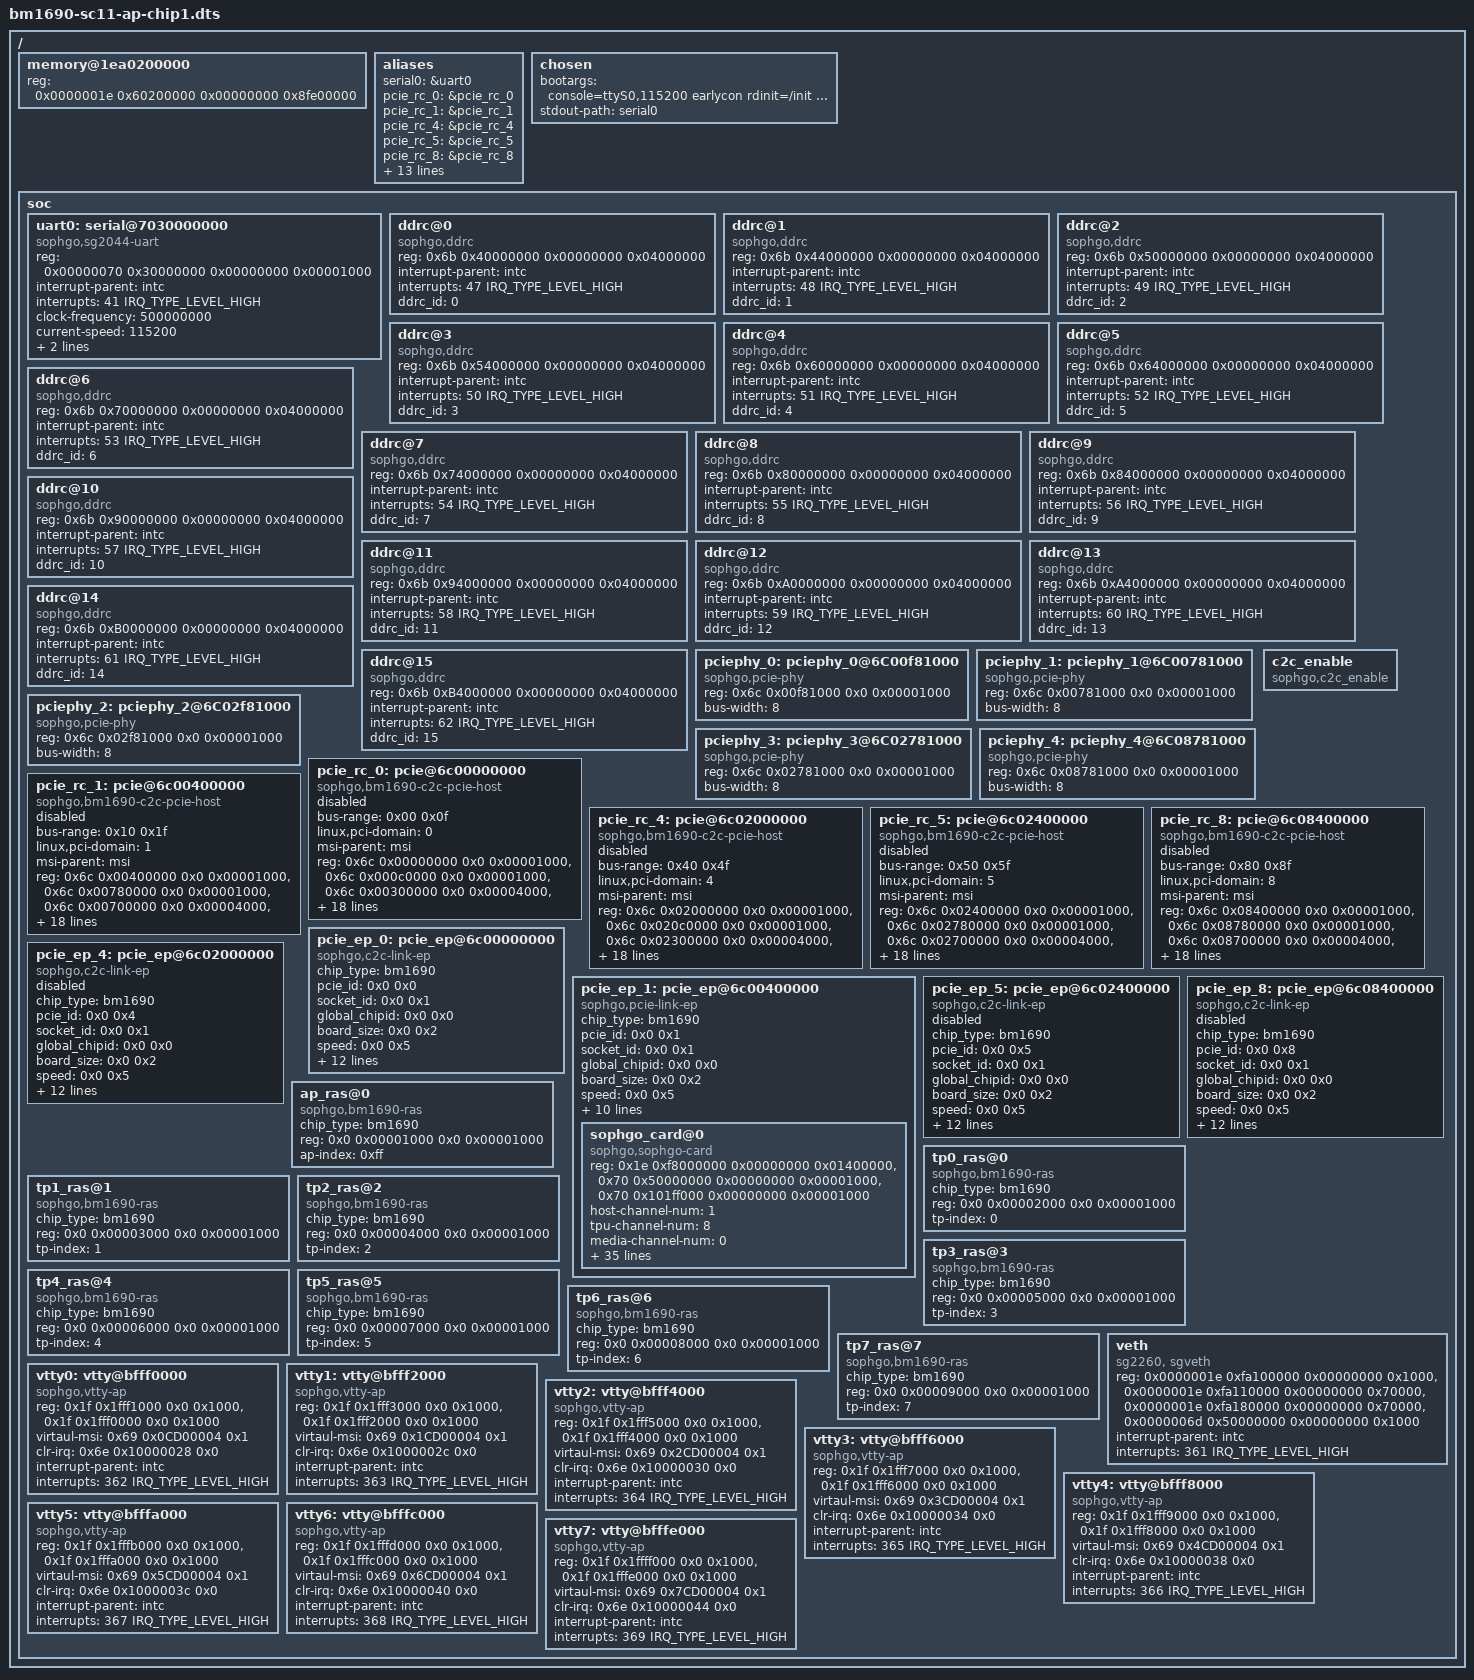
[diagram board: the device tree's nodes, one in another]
// SPDX-License-Identifier: (GPL-2.0 OR MIT)
/*
 * Copyright (C) 2022 Sophgo Technology Inc. All rights reserved.
 */

/dts-v1/;
#include <dt-bindings/interrupt-controller/irq.h>
#include <dt-bindings/reset/sophgo,sg2044-reset.h>
#include <dt-bindings/clock/sophgo,sg2044-clock.h>
#include "bm1690-cpu-ap.dtsi"
#include "bm1690-clock.dtsi"
#include "sg2044-pinctrl.dtsi"
#include "sg2044-peri-sys.dtsi"
#include "bm1690-pcie-msi.dtsi"

/delete-node/ &emmc;

/ {
	/delete-node/ memory@80200000;
	memory@1ea0200000 {
		device_type = "memory";
		reg = <0x0000001e 0x60200000 0x00000000 0x8fe00000>;
	};

	aliases {
		serial0 = &uart0;
		pcie_rc_0 = &pcie_rc_0;
		pcie_rc_1 = &pcie_rc_1;
		pcie_rc_4 = &pcie_rc_4;
		pcie_rc_5 = &pcie_rc_5;
		pcie_rc_8 = &pcie_rc_8;
		pcie_ep_0 = &pcie_ep_0;
		pcie_ep_1 = &pcie_ep_1;
		pcie_ep_4 = &pcie_ep_4;
		pcie_ep_5 = &pcie_ep_5;
		pcie_ep_8 = &pcie_ep_8;
		vtty0 = &vtty0;
		vtty1 = &vtty1;
		vtty2 = &vtty2;
		vtty3 = &vtty3;
		vtty4 = &vtty4;
		vtty5 = &vtty5;
		vtty6 = &vtty6;
		vtty7 = &vtty7;
	};

	chosen {
		bootargs = "console=ttyS0,115200 earlycon rdinit=/init root=/dev/ram0 rw initrd=0x1eab000000,64M maxcpus=4";
		stdout-path = "serial0";
	};

	soc {
		uart0: serial@7030000000 {
			compatible = "sophgo,sg2044-uart", "snps,dw-apb-uart";
			reg = <0x00000070 0x30000000 0x00000000 0x00001000>;
			interrupt-parent = <&intc>;
			interrupts = <41 IRQ_TYPE_LEVEL_HIGH>;
			clock-frequency = <500000000>;
			current-speed = <115200>;
			reg-shift = <2>;
			reg-io-width = <4>;
		};

		ddrc@0 {
			compatible = "sophgo,ddrc";

			reg = <0x6b 0x40000000 0x00000000 0x04000000>;
			interrupt-parent = <&intc>;
			interrupts = <47 IRQ_TYPE_LEVEL_HIGH>;
			// trigger_error_index = <0x0201060c>;
			ddrc_id = <0>;
		};
		ddrc@1 {
			compatible = "sophgo,ddrc";

			reg = <0x6b 0x44000000 0x00000000 0x04000000>;
			interrupt-parent = <&intc>;
			interrupts = <48 IRQ_TYPE_LEVEL_HIGH>;
			// trigger_error_index = <0x0201060c>;
			ddrc_id = <1>;
		};
		ddrc@2 {
			compatible = "sophgo,ddrc";

			reg = <0x6b 0x50000000 0x00000000 0x04000000>;
			interrupt-parent = <&intc>;
			interrupts = <49 IRQ_TYPE_LEVEL_HIGH>;
			// trigger_error_index = <0x0201060c>;
			ddrc_id = <2>;
		};
		ddrc@3 {
			compatible = "sophgo,ddrc";

			reg = <0x6b 0x54000000 0x00000000 0x04000000>;
			interrupt-parent = <&intc>;
			interrupts = <50 IRQ_TYPE_LEVEL_HIGH>;
			// trigger_error_index = <0x0201060c>;
			ddrc_id = <3>;
		};
		ddrc@4 {
			compatible = "sophgo,ddrc";

			reg = <0x6b 0x60000000 0x00000000 0x04000000>;
			interrupt-parent = <&intc>;
			interrupts = <51 IRQ_TYPE_LEVEL_HIGH>;
			// trigger_error_index = <0x0201060c>;
			ddrc_id = <4>;
		};
		ddrc@5 {
			compatible = "sophgo,ddrc";

			reg = <0x6b 0x64000000 0x00000000 0x04000000>;
			interrupt-parent = <&intc>;
			interrupts = <52 IRQ_TYPE_LEVEL_HIGH>;
			// trigger_error_index = <0x0201060c>;
			ddrc_id = <5>;
		};
		ddrc@6 {
			compatible = "sophgo,ddrc";

			reg = <0x6b 0x70000000 0x00000000 0x04000000>;
			interrupt-parent = <&intc>;
			interrupts = <53 IRQ_TYPE_LEVEL_HIGH>;
			// trigger_error_index = <0x0201060c>;
			ddrc_id = <6>;
		};
		ddrc@7 {
			compatible = "sophgo,ddrc";

			reg = <0x6b 0x74000000 0x00000000 0x04000000>;
			interrupt-parent = <&intc>;
			interrupts = <54 IRQ_TYPE_LEVEL_HIGH>;
			// trigger_error_index = <0x0201060c>;
			ddrc_id = <7>;
		};
		ddrc@8 {
			compatible = "sophgo,ddrc";

			reg = <0x6b 0x80000000 0x00000000 0x04000000>;
			interrupt-parent = <&intc>;
			interrupts = <55 IRQ_TYPE_LEVEL_HIGH>;
			// trigger_error_index = <0x0201060c>;
			ddrc_id = <8>;
		};
		ddrc@9 {
			compatible = "sophgo,ddrc";

			reg = <0x6b 0x84000000 0x00000000 0x04000000>;
			interrupt-parent = <&intc>;
			interrupts = <56 IRQ_TYPE_LEVEL_HIGH>;
			// trigger_error_index = <0x0201060c>;
			ddrc_id = <9>;
		};
		ddrc@10 {
			compatible = "sophgo,ddrc";

			reg = <0x6b 0x90000000 0x00000000 0x04000000>;
			interrupt-parent = <&intc>;
			interrupts = <57 IRQ_TYPE_LEVEL_HIGH>;
			// trigger_error_index = <0x0201060c>;
			ddrc_id = <10>;
		};
		ddrc@11 {
			compatible = "sophgo,ddrc";

			reg = <0x6b 0x94000000 0x00000000 0x04000000>;
			interrupt-parent = <&intc>;
			interrupts = <58 IRQ_TYPE_LEVEL_HIGH>;
			// trigger_error_index = <0x0201060c>;
			ddrc_id = <11>;
		};
		ddrc@12 {
			compatible = "sophgo,ddrc";

			reg = <0x6b 0xA0000000 0x00000000 0x04000000>;
			interrupt-parent = <&intc>;
			interrupts = <59 IRQ_TYPE_LEVEL_HIGH>;
			// trigger_error_index = <0x0201060c>;
			ddrc_id = <12>;
		};
		ddrc@13 {
			compatible = "sophgo,ddrc";

			reg = <0x6b 0xA4000000 0x00000000 0x04000000>;
			interrupt-parent = <&intc>;
			interrupts = <60 IRQ_TYPE_LEVEL_HIGH>;
			// trigger_error_index = <0x0201060c>;
			ddrc_id = <13>;
		};
		ddrc@14 {
			compatible = "sophgo,ddrc";

			reg = <0x6b 0xB0000000 0x00000000 0x04000000>;
			interrupt-parent = <&intc>;
			interrupts = <61 IRQ_TYPE_LEVEL_HIGH>;
			// trigger_error_index = <0x0201060c>;
			ddrc_id = <14>;
		};
		ddrc@15 {
			compatible = "sophgo,ddrc";

			reg = <0x6b 0xB4000000 0x00000000 0x04000000>;
			interrupt-parent = <&intc>;
			interrupts = <62 IRQ_TYPE_LEVEL_HIGH>;
			// trigger_error_index = <0x0201060c>;
			ddrc_id = <15>;
		};

		//c2c0 x8/x4_1
		pciephy_0: pciephy_0@6C00f81000 {
			compatible = "sophgo,pcie-phy";
			#phy-cells = <1>;
			reg = <0x6c 0x00f81000 0x0 0x00001000>;
			bus-width = <8>;
		};
		//c2c0 x8/x4_0
		pciephy_1: pciephy_1@6C00781000 {
			compatible = "sophgo,pcie-phy";
			#phy-cells = <1>;
			reg = <0x6c 0x00781000 0x0 0x00001000>;
			bus-width = <8>;
		};
		//c2c1 x8/x4_1
		pciephy_2: pciephy_2@6C02f81000 {
			compatible = "sophgo,pcie-phy";
			#phy-cells = <1>;
			reg =	<0x6c 0x02f81000 0x0 0x00001000>;
			bus-width = <8>;
		};
		//c2c1 x8/x4_0
		pciephy_3: pciephy_3@6C02781000 {
			compatible = "sophgo,pcie-phy";
			#phy-cells = <1>;
			reg = <0x6c 0x02781000 0x0 0x00001000>;
			bus-width = <8>;
		};
		//cxp x8/x4
		pciephy_4: pciephy_4@6C08781000 {
			compatible = "sophgo,pcie-phy";
			#phy-cells = <1>;
			reg = <0x6c 0x08781000 0x0 0x00001000>;
			bus-width = <8>;
		};
		c2c_enable {
			compatible = "sophgo,c2c_enable";
		};
		//c2c0_x8_1 c2c rc (on board)
		pcie_rc_0: pcie@6c00000000 {
			compatible = "sophgo,bm1690-c2c-pcie-host";
			device_type = "pci";
			#address-cells = <3>;
			#size-cells = <2>;
			bus-range = <0x00 0x0f>;
			linux,pci-domain = <0>;
			msi-parent = <&msi>;
			reg = <0x6c 0x00000000  0x0 0x00001000>,
			<0x6c 0x000c0000  0x0 0x00001000>,
			<0x6c 0x00300000  0x0 0x00004000>,
			<0x48 0x00000000  0x0 0x00001000>;
			reg-names = "dbi", "ctrl_base", "atu", "config";
			c2c_top =  <0x6C 0x007D0000  0x0 0x00001000>;
			dma-coherent;
			pcie-card;
			c2c0_x8_1;
			// IO, check IO_SPACE_LIMIT
			// 32bit prefetchable memory
			// 32bit non-prefetchable memory
			// 64bit prefetchable memory
			// 64bit non-prefetchable memory
			phys = <&pciephy_0 0>;
			phy-names = "pcie-phy";
			max-link-speed = <4>;
			num-lanes = <8>;
			prst = <&port0a 2 0>;
			ranges = <0x01000000 0x0  0x00000000  0x48 0x10000000  0x0 0x00400000>,
				<0x42000000 0x0  0x20000000  0x48  0x20000000  0x0 0x04000000>,
				<0x02000000 0x0  0x24000000  0x48  0x24000000  0x0 0x04000000>,
				<0x43000000 0x4a 0x00000000  0x4a 0x00000000  0x2 0x00000000>,
				<0x03000000 0x49 0x00000000  0x49 0x00000000  0x1 0x00000000>;
			dma-ranges = <0x03000000 0x0 0x0 0x0 0x0 0x40 0x0>,
				<0x43000000 0x40 0x0 0x40 0x0 0x40 0x0>;
			cfg_range = <0x6c 0x00000000 0x6c 0x003fffff>;
			slv_range = <0x48 0x00000000 0x4b 0xffffffff>;
			cdma-reg = <0x6c 0x007b0000 0x0 0x10000>;

			socket_id = <0x0 0x1>;
			global_chipid = <0x0 0x1>;
			board_size = <0x0 0x2>;

			status = "disable";
		};
		//c2c0_x8_0
		pcie_rc_1: pcie@6c00400000 {
			compatible = "sophgo,bm1690-c2c-pcie-host";
			device_type = "pci";
			#address-cells = <3>;
			#size-cells = <2>;
			bus-range = <0x10 0x1f>;
			linux,pci-domain = <1>;
			msi-parent = <&msi>;
			reg = <0x6c 0x00400000  0x0 0x00001000>,
			<0x6c 0x00780000 0x0 0x00001000>,
			<0x6c 0x00700000  0x0 0x00004000>,
			<0x40 0x00000000  0x0 0x00001000>;
			reg-names = "dbi", "ctrl_base", "atu", "config";
			c2c_top =  <0x6C 0x007D0000  0x0 0x00001000>;
			dma-coherent;
			pcie-card;
			c2c0_x8_0;
			// IO, check IO_SPACE_LIMIT
			// 32bit prefetchable memory
			// 32bit non-prefetchable memory
			// 64bit prefetchable memory
			// 64bit non-prefetchable memory
			phys = <&pciephy_1 0>;
			phy-names = "pcie-phy";
			max-link-speed = <4>;
			num-lanes = <8>;
			prst = <&port0a 6 0>;
			ranges = <0x01000000 0x0  0x00000000  0x40 0x10000000  0x0 0x00400000>,
				<0x42000000 0x0  0x20000000  0x40  0x20000000  0x0 0x04000000>,
				<0x02000000 0x0  0x24000000  0x40  0x24000000  0x0 0x04000000>,
				<0x43000000 0x42 0x00000000  0x42 0x00000000  0x2 0x00000000>,
				<0x03000000 0x41 0x00000000  0x41 0x00000000  0x1 0x00000000>;
			dma-ranges = <0x03000000 0x0 0x0 0x0 0x0 0x40 0x0>,
				<0x43000000 0x40 0x0 0x40 0x0 0x40 0x0>;
			cfg_range = <0x6c 0x00000000 0x6c 0x003fffff>;
			slv_range = <0x40 0x00000000 0x43 0xffffffff>;
			cdma-reg = <0x6c 0x00790000 0x0 0x10000>;

			socket_id = <0x0 0x1>;
			global_chipid = <0x0 0x1>;
			board_size = <0x0 0x2>;

			status = "disable";
		};
		//c2c1_x8_1
		pcie_rc_4: pcie@6c02000000 {
			compatible = "sophgo,bm1690-c2c-pcie-host";
			device_type = "pci";
			#address-cells = <3>;
			#size-cells = <2>;
			bus-range = <0x40 0x4f>;
			linux,pci-domain = <4>;
			msi-parent = <&msi>;
			reg = <0x6c 0x02000000  0x0 0x00001000>,
			<0x6c 0x020c0000  0x0 0x00001000>,
			<0x6c 0x02300000  0x0 0x00004000>,
			<0x58 0x00000000  0x0 0x00001000>;
			reg-names = "dbi", "ctrl_base", "atu", "config";
			c2c_top = <0x6C 0x027D0000  0x0 0x00001000>;
			dma-coherent;
			pcie-card;
			c2c1_x8_1;
			// IO, check IO_SPACE_LIMIT
			// 32bit prefetchable memory
			// 32bit non-prefetchable memory
			// 64bit prefetchable memory
			// 64bit non-prefetchable memory
			phys = <&pciephy_2 0>;
			phy-names = "pcie-phy";
			max-link-speed = <4>;
			num-lanes = <8>;
			prst = <&port0a 22 0>;
			ranges = <0x01000000 0x0  0x00000000  0x58 0x10000000  0x0 0x00400000>,
				<0x42000000 0x0  0x20000000  0x58  0x20000000  0x0 0x04000000>,
				<0x02000000 0x0  0x24000000  0x58  0x24000000  0x0 0x04000000>,
				<0x43000000 0x5a 0x00000000  0x5a 0x00000000  0x2 0x00000000>,
				<0x03000000 0x59 0x00000000  0x59 0x00000000  0x1 0x00000000>;
			dma-ranges = <0x03000000 0x0 0x0 0x0 0x0 0x40 0x0>,
				<0x43000000 0x40 0x0 0x40 0x0 0x40 0x0>;
			cfg_range = <0x6c 0x02000000 0x6c 0x03ffffff>;
			slv_range = <0x58 0x00000000 0x5b 0xffffffff>;
			cdma-reg = <0x6c 0x027b0000 0x0 0x10000>;

			socket_id = <0x0 0x1>;
			global_chipid = <0x0 0x1>;
			board_size = <0x0 0x2>;

			status = "disable";
		};
		//c2c1_x8_0
		pcie_rc_5: pcie@6c02400000 {
			compatible = "sophgo,bm1690-c2c-pcie-host";
			device_type = "pci";
			#address-cells = <3>;
			#size-cells = <2>;
			bus-range = <0x50 0x5f>;
			linux,pci-domain = <5>;
			msi-parent = <&msi>;
			reg = <0x6c 0x02400000  0x0 0x00001000>,
			<0x6c 0x02780000  0x0 0x00001000>,
			<0x6c 0x02700000  0x0 0x00004000>,
			<0x50 0x00000000  0x0 0x00001000>;
			reg-names = "dbi", "ctrl_base", "atu", "config";
			c2c_top = <0x6C 0x027D0000  0x0 0x00001000>;
			dma-coherent;
			pcie-card;
			c2c1_x8_0;
			// IO, check IO_SPACE_LIMIT
			// 32bit prefetchable memory
			// 32bit non-prefetchable memory
			// 64bit prefetchable memory
			// 64bit non-prefetchable memory
			phys = <&pciephy_3 0>;
			phy-names = "pcie-phy";
			max-link-speed = <4>;
			num-lanes = <8>;
			prst = <&port0a 20 0>;
			ranges = <0x01000000 0x0  0x00000000  0x50 0x10000000  0x0 0x00400000>,
				<0x42000000 0x0  0x20000000  0x50 0x20000000  0x0 0x04000000>,
				<0x02000000 0x0  0x24000000  0x50 0x24000000  0x0 0x04000000>,
				<0x43000000 0x52 0x00000000  0x52 0x00000000  0x2 0x00000000>,
				<0x03000000 0x51 0x00000000  0x51 0x00000000  0x1 0x00000000>;
			dma-ranges = <0x03000000 0x0 0x0 0x0 0x0 0x40 0x0>,
				<0x43000000 0x40 0x0 0x40 0x0 0x40 0x0>;
			cfg_range = <0x6c 0x02000000 0x6c 0x03ffffff>;
			slv_range = <0x50 0x00000000 0x53 0xffffffff>;
			cdma-reg = <0x6c 0x02790000 0x0 0x10000>;

			socket_id = <0x0 0x1>;
			global_chipid = <0x0 0x1>;
			board_size = <0x0 0x2>;

			status = "disable";
		};
		//cxp
		pcie_rc_8: pcie@6c08400000 {
			compatible = "sophgo,bm1690-c2c-pcie-host";
			device_type = "pci";
			#address-cells = <3>;
			#size-cells = <2>;
			bus-range = <0x80 0x8f>;
			linux,pci-domain = <8>;
			msi-parent = <&msi>;
			reg = <0x6c 0x08400000  0x0 0x00001000>,
			<0x6c 0x08780000  0x0 0x00001000>,
			<0x6c 0x08700000  0x0 0x00004000>,
			<0x60 0x00000000  0x0 0x00010000>;
			reg-names = "dbi", "ctrl_base", "atu", "config";
			c2c_top = <0x6C 0x087D0000  0x0 0x00001000>;
			dma-coherent;
			pcie-card;
			cxp_x8;
			// IO, check IO_SPACE_LIMIT
			// 32bit prefetchable memory
			// 32bit non-prefetchable memory
			// 64bit prefetchable memory
			// 64bit non-prefetchable memory
			phys = <&pciephy_4 0>;
			phy-names = "pcie-phy";
			max-link-speed = <4>;
			num-lanes = <8>;
			prst = <&port0a 7 0>;
			ranges = <0x01000000 0x0  0x00000000  0x60 0x10000000  0x0 0x00400000>,
				<0x42000000 0x0  0x20000000  0x60 0x20000000  0x0 0x04000000>,
				<0x02000000 0x0  0x24000000  0x60 0x24000000  0x0 0x04000000>,
				<0x43000000 0x62 0x00000000  0x62 0x00000000  0x2 0x00000000>,
				<0x03000000 0x61 0x00000000  0x61 0x00000000  0x1 0x00000000>;
			dma-ranges = <0x03000000 0x0 0x0 0x0 0x0 0x40 0x0>,
				<0x43000000 0x40 0x0 0x40 0x0 0x40 0x0>;
			cfg_range = <0x6c 0x08000000 0x6c 0x09ffffff>;
			slv_range = <0x60 0x00000000 0x67 0xffffffff>;
			cdma-reg = <0x6c 0x087a0000 0x0 0x10000>;

			socket_id = <0x0 0x1>;
			global_chipid = <0x0 0x1>;
			board_size = <0x0 0x2>;

			status = "disable";
		};
		//c2c0_x8_1 c2c ep (on board)
		pcie_ep_0: pcie_ep@6c00000000 {
			compatible = "sophgo,c2c-link-ep";
			chip_type = "bm1690";
			#address-cells = <2>;
			#size-cells = <2>;
			ranges;//this is must, must, must, must
			pcie_id = <0x0 0x0>;
			socket_id = <0x0 0x1>;
			global_chipid = <0x0 0x0>;
			board_size = <0x0 0x2>;
			speed = <0x0 0x5>;
			lane_num = <0x0 0x8>;
			func_num = <0x0 0x1>;
			c2c0_x8_1;
			//pcie1
			reg =	<0x6c 0x00000000  0x0 0x00300000>,
				<0x6c 0x00300000  0x0 0x00004000>,
				<0x6c 0x000c0000  0x0 0x00001000>;
			reg-names = "dbi", "atu", "ctrl";
			c2c_config_range = <0x6c 0x00000000 0x00000000 0x01ffffff>;
			c2c_top = <0x6c 0x007d0000  0x0 0x00001000>;
			cdma-reg = <0x6c 0x007b0000 0x0 0x10000>;
			phys = <&pciephy_0 0>;
			phy-names = "pcie-phy";
			perst-gpios = <&port0a 24 0>;
			status = "okay";
		};
		//c2c0_x8_0
		pcie_ep_1: pcie_ep@6c00400000 {
			compatible = "sophgo,pcie-link-ep";
			chip_type = "bm1690";
			#address-cells = <2>;
			#size-cells = <2>;
			ranges;//this is must, must, must, must
			pcie_id = <0x0 0x1>;
			socket_id = <0x0 0x1>;
			global_chipid = <0x0 0x0>;
			board_size = <0x0 0x2>;
			speed = <0x0 0x5>;
			lane_num = <0x0 0x8>;
			func_num = <0x0 0x1>;
			c2c0_x8_0;
			//pcie1
			reg =   <0x6c 0x00400000 0x00000000 0x00300000>,
				<0x6c 0x00700000 0x00000000 0x00004000>,
				<0x6c 0x00780000 0x00000000 0x00001000>;
			reg-names = "dbi", "atu", "ctrl";
			c2c_config_range = <0x6c 0x00000000 0x00000000 0x01ffffff>;
			c2c_top = <0x6c 0x007d0000  0x0 0x00001000>;
			cdma-reg = <0x6c 0x00790000 0x0 0x10000>;
			status = "okay";
			sophgo_card@0 {
				compatible = "sophgo,sophgo-card";
				reg = <0x1e  0xf8000000 0x00000000 0x01400000>,
					<0x70 0x50000000 0x00000000 0x00001000>,
					<0x70 0x101ff000 0x00000000 0x00001000>;
				reg-names = "share-memory", "top-reg", "config_file";
				host-channel-num = <1>;
				tpu-channel-num = <8>;
				media-channel-num = <0>;
				tx-channel = <0x0 0x2 0x4 0x6 0x8 0xa 0xc 0xe 0x10>;
				rx-channel = <0x1 0x3 0x5 0x7 0x9 0xb 0xd 0xf 0x11>;
				channel-size = <0x100000>;
				share-memory-type = <1>;
				interrupt-parent = <&intc>;
				interrupts = <352 IRQ_TYPE_EDGE_RISING>,
						<353 IRQ_TYPE_EDGE_RISING>,
						<354 IRQ_TYPE_EDGE_RISING>,
						<355 IRQ_TYPE_EDGE_RISING>,
						<356 IRQ_TYPE_EDGE_RISING>,
						<357 IRQ_TYPE_EDGE_RISING>,
						<358 IRQ_TYPE_EDGE_RISING>,
						<359 IRQ_TYPE_EDGE_RISING>,
						<360 IRQ_TYPE_EDGE_RISING>;
				clr-irq = <0x6E 0x10000000 0x00000000 0x00000000>,
						<0x6E 0x10000004 0x00000000 0x00000000>,
						<0x6E 0x10000008 0x00000000 0x00000000>,
						<0x6E 0x1000000c 0x00000000 0x00000000>,
						<0x6E 0x10000010 0x00000000 0x00000000>,
						<0x6E 0x10000014 0x00000000 0x00000000>,
						<0x6E 0x10000018 0x00000000 0x00000000>,
						<0x6E 0x1000001c 0x00000000 0x00000000>,
						<0x6E 0x10000020 0x00000000 0x00000000>;
				virtual-msi = <0x0 0x0 0x00000000 0x00000000>,
						<0x69 0x0cd00000 0x00000000 0x00000001>,
						<0x69 0x1cd00000 0x00000000 0x00000001>,
						<0x69 0x2cd00000 0x00000000 0x00000001>,
						<0x69 0x3cd00000 0x00000000 0x00000001>,
						<0x69 0x4cd00000 0x00000000 0x00000001>,
						<0x69 0x5cd00000 0x00000000 0x00000001>,
						<0x69 0x6cd00000 0x00000000 0x00000001>,
						<0x69 0x7cd00000 0x00000000 0x00000001>;
			};
		};
		//c2c1_x8_1
		pcie_ep_4: pcie_ep@6c02000000 {
			compatible = "sophgo,c2c-link-ep";
			chip_type = "bm1690";
			#address-cells = <2>;
			#size-cells = <2>;
			ranges;//this is must, must, must, must
			pcie_id = <0x0 0x4>;
			socket_id = <0x0 0x1>;
			global_chipid = <0x0 0x0>;
			board_size = <0x0 0x2>;
			speed = <0x0 0x5>;
			lane_num = <0x0 0x8>;
			func_num = <0x0 0x1>;
			c2c1_x8_1;
			//pcie1
			reg =	<0x6c 0x02000000  0x0 0x00300000>,
				<0x6c 0x02300000  0x0 0x00004000>,
				<0x6c 0x020c0000  0x0 0x00001000>;
			reg-names = "dbi", "atu", "ctrl";
			c2c_config_range = <0x6c 0x02000000 0x00000000 0x01ffffff>;
			c2c_top = <0x6c 0x027d0000  0x0 0x00001000>;
			cdma-reg = <0x6c 0x027b0000 0x0 0x10000>;
			phys = <&pciephy_2 0>;
			phy-names = "pcie-phy";
			perst-gpios = <&port0a 22 0>;
			status = "disable";
		};
		//c2c1_x8_0
		pcie_ep_5: pcie_ep@6c02400000 {
			compatible = "sophgo,c2c-link-ep";
			chip_type = "bm1690";
			#address-cells = <2>;
			#size-cells = <2>;
			ranges;//this is must, must, must, must
			pcie_id = <0x0 0x5>;
			socket_id = <0x0 0x1>;
			global_chipid = <0x0 0x0>;
			board_size = <0x0 0x2>;
			speed = <0x0 0x5>;
			lane_num = <0x0 0x8>;
			func_num = <0x0 0x1>;
			c2c1_x8_0;
			//pcie1
			reg =	<0x6c 0x02400000  0x0 0x00300000>,
				<0x6c 0x02700000  0x0 0x00004000>,
				<0x6c 0x02780000  0x0 0x00001000>;
			reg-names = "dbi", "atu", "ctrl";
			c2c_config_range = <0x6c 0x02000000 0x00000000 0x01ffffff>;
			c2c_top = <0x6c 0x027d0000  0x0 0x00001000>;
			cdma-reg = <0x6c 0x02790000 0x0 0x10000>;
			phys = <&pciephy_3 0>;
			phy-names = "pcie-phy";
			perst-gpios = <&port0a 20 0>;
			status = "disable";
		};
		//cxp
		pcie_ep_8: pcie_ep@6c08400000 {
			compatible = "sophgo,c2c-link-ep";
			chip_type = "bm1690";
			#address-cells = <2>;
			#size-cells = <2>;
			ranges;//this is must, must, must, must
			pcie_id = <0x0 0x8>;
			socket_id = <0x0 0x1>;
			global_chipid = <0x0 0x0>;
			board_size = <0x0 0x2>;
			speed = <0x0 0x5>;
			lane_num = <0x0 0x8>;
			func_num = <0x0 0x1>;
			cxp_x8;
			//pcie1
			reg =	<0x6c 0x08400000  0x0 0x00300000>,
				<0x6c 0x08700000  0x0 0x00004000>,
				<0x6c 0x08780000  0x0 0x00001000>;
			reg-names = "dbi", "atu", "ctrl";
			c2c_config_range = <0x6c 0x08000000 0x00000000 0x01ffffff>;
			c2c_top = <0x6c 0x087d0000  0x0 0x00001000>;
			cdma-reg = <0x6c 0x087a0000 0x0 0x10000>;
			phys = <&pciephy_4 0>;
			phy-names = "pcie-phy";
			perst-gpios = <&port0a 7 0>;
			status = "disable";
		};

		ap_ras@0 {
			compatible = "sophgo,bm1690-ras";
			chip_type = "bm1690";
			#address-cells = <2>;
			#size-cells = <2>;

			reg = <0x0 0x00001000 0x0 0x00001000>;
			ap-index = <0xff>;
		};

		tp0_ras@0 {
			compatible = "sophgo,bm1690-ras";
			chip_type = "bm1690";
			#address-cells = <2>;
			#size-cells = <2>;

			reg = <0x0 0x00002000 0x0 0x00001000>;
			tp-index = <0>;
		};

		tp1_ras@1 {
			compatible = "sophgo,bm1690-ras";
			chip_type = "bm1690";
			#address-cells = <2>;
			#size-cells = <2>;

			reg = <0x0 0x00003000 0x0 0x00001000>;
			tp-index = <1>;
		};

		tp2_ras@2 {
			compatible = "sophgo,bm1690-ras";
			chip_type = "bm1690";
			#address-cells = <2>;
			#size-cells = <2>;

			reg = <0x0 0x00004000 0x0 0x00001000>;
			tp-index = <2>;
		};

		tp3_ras@3 {
			compatible = "sophgo,bm1690-ras";
			chip_type = "bm1690";
			#address-cells = <2>;
			#size-cells = <2>;

			reg = <0x0 0x00005000 0x0 0x00001000>;
			tp-index = <3>;
		};

		tp4_ras@4 {
			compatible = "sophgo,bm1690-ras";
			chip_type = "bm1690";
			#address-cells = <2>;
			#size-cells = <2>;

			reg = <0x0 0x00006000 0x0 0x00001000>;
			tp-index = <4>;
		};

		tp5_ras@5 {
			compatible = "sophgo,bm1690-ras";
			chip_type = "bm1690";
			#address-cells = <2>;
			#size-cells = <2>;

			reg = <0x0 0x00007000 0x0 0x00001000>;
			tp-index = <5>;
		};

		tp6_ras@6 {
			compatible = "sophgo,bm1690-ras";
			chip_type = "bm1690";
			#address-cells = <2>;
			#size-cells = <2>;

			reg = <0x0 0x00008000 0x0 0x00001000>;
			tp-index = <6>;
		};

		tp7_ras@7 {
			compatible = "sophgo,bm1690-ras";
			chip_type = "bm1690";
			#address-cells = <2>;
			#size-cells = <2>;

			reg = <0x0 0x00009000 0x0 0x00001000>;
			tp-index = <7>;
		};

		veth:  veth {
			compatible = "sg2260, sgveth";
			reg = <0x0000001e 0xfa100000 0x00000000 0x1000>,
				<0x0000001e 0xfa110000 0x00000000 0x70000>,
				<0x0000001e 0xfa180000 0x00000000 0x70000>,
				<0x0000006d 0x50000000 0x00000000 0x1000>;
			reg-names = "shm_reg", "rx_reg", "tx_reg", "irq_reg";
			interrupt-parent = <&intc>;
			interrupts = <361 IRQ_TYPE_LEVEL_HIGH>;
			interrupt-names = "rx";
			status = "okay";
		};
		vtty0: vtty@bfff0000 {
			compatible = "sophgo,vtty-ap";
			#size-cells = <0x2>;
			#address-cells = <0x2>;
			reg = <0x1f 0x1fff1000 0x0 0x1000>,
				<0x1f 0x1fff0000 0x0 0x1000>;
			virtaul-msi = <0x69 0x0CD00004 0x1>;
			clr-irq = <0x6e 0x10000028 0x0>;
			interrupt-parent = <&intc>;
			interrupts = <362 IRQ_TYPE_LEVEL_HIGH>;
		};
		vtty1: vtty@bfff2000 {
			compatible = "sophgo,vtty-ap";
			#size-cells = <0x2>;
			#address-cells = <0x2>;
			reg = <0x1f 0x1fff3000 0x0 0x1000>,
				<0x1f 0x1fff2000 0x0 0x1000>;
			virtaul-msi = <0x69 0x1CD00004 0x1>;
			clr-irq = <0x6e 0x1000002c 0x0>;
			interrupt-parent = <&intc>;
			interrupts = <363 IRQ_TYPE_LEVEL_HIGH>;
		};
		vtty2: vtty@bfff4000 {
			compatible = "sophgo,vtty-ap";
			#size-cells = <0x2>;
			#address-cells = <0x2>;
			reg = <0x1f 0x1fff5000 0x0 0x1000>,
				<0x1f 0x1fff4000 0x0 0x1000>;
			virtaul-msi = <0x69 0x2CD00004 0x1>;
			clr-irq = <0x6e 0x10000030 0x0>;
			interrupt-parent = <&intc>;
			interrupts = <364 IRQ_TYPE_LEVEL_HIGH>;
		};
		vtty3: vtty@bfff6000 {
			compatible = "sophgo,vtty-ap";
			#size-cells = <0x2>;
			#address-cells = <0x2>;
			reg = <0x1f 0x1fff7000 0x0 0x1000>,
				<0x1f 0x1fff6000 0x0 0x1000>;
			virtaul-msi = <0x69 0x3CD00004 0x1>;
			clr-irq = <0x6e 0x10000034 0x0>;
			interrupt-parent = <&intc>;
			interrupts = <365 IRQ_TYPE_LEVEL_HIGH>;
		};
		vtty4: vtty@bfff8000 {
			compatible = "sophgo,vtty-ap";
			#size-cells = <0x2>;
			#address-cells = <0x2>;
			reg = <0x1f 0x1fff9000 0x0 0x1000>,
				<0x1f 0x1fff8000 0x0 0x1000>;
			virtaul-msi = <0x69 0x4CD00004 0x1>;
			clr-irq = <0x6e 0x10000038 0x0>;
			interrupt-parent = <&intc>;
			interrupts = <366 IRQ_TYPE_LEVEL_HIGH>;
		};
		vtty5: vtty@bfffa000 {
			compatible = "sophgo,vtty-ap";
			#size-cells = <0x2>;
			#address-cells = <0x2>;
			reg = <0x1f 0x1fffb000 0x0 0x1000>,
				<0x1f 0x1fffa000 0x0 0x1000>;
			virtaul-msi = <0x69 0x5CD00004 0x1>;
			clr-irq = <0x6e 0x1000003c 0x0>;
			interrupt-parent = <&intc>;
			interrupts = <367 IRQ_TYPE_LEVEL_HIGH>;
		};
		vtty6: vtty@bfffc000 {
			compatible = "sophgo,vtty-ap";
			#size-cells = <0x2>;
			#address-cells = <0x2>;
			reg = <0x1f 0x1fffd000 0x0 0x1000>,
				<0x1f 0x1fffc000 0x0 0x1000>;
			virtaul-msi = <0x69 0x6CD00004 0x1>;
			clr-irq = <0x6e 0x10000040 0x0>;
			interrupt-parent = <&intc>;
			interrupts = <368 IRQ_TYPE_LEVEL_HIGH>;
		};
		vtty7: vtty@bfffe000 {
			compatible = "sophgo,vtty-ap";
			#size-cells = <0x2>;
			#address-cells = <0x2>;
			reg = <0x1f 0x1ffff000 0x0 0x1000>,
				<0x1f 0x1fffe000 0x0 0x1000>;
			virtaul-msi = <0x69 0x7CD00004 0x1>;
			clr-irq = <0x6e 0x10000044 0x0>;
			interrupt-parent = <&intc>;
			interrupts = <369 IRQ_TYPE_LEVEL_HIGH>;
		};
	};
};
